# XMC4300 register map
Vendor: Infineon; File version: 1.1.0 (Reference Manual v1.1)
CPU: CM4 r2p0, little endian, MPU, FPU, 6 interrupt priority bits
Registers are 32-bit, read-write, reset 0x0 unless marked. A register's access mark holds for its fields unless they carry their own. Offsets are from the block's base; [hi:lo] are bit positions; 'fields as' and 'values as' point back to an identical list.

## SCU_CLK — System Control Unit
Base 0x50004600
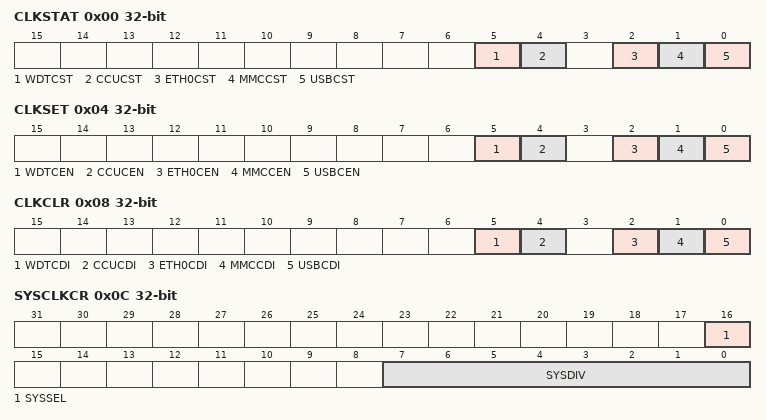
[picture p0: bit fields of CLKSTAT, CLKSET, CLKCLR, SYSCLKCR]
0x00 CLKSTAT ro — Clock Status Register
  [all] fields
    0=Const_0 (Clock disabled); 1=Const_1 (Clock enabled)
  [5] WDTCST — WDT Clock Status
  [4] CCUCST — CCU Clock Status
  [2] ETH0CST — Ethernet Clock Status
  [1] MMCCST — MMC Clock Status
  [0] USBCST — USB Clock Status
0x04 CLKSET wo
  [all] fields
    0=Const_0 (No effect); 1=Const_1 (Enable)
  [5] WDTCEN — WDT Clock Enable
  [4] CCUCEN — CCU Clock Enable
  [2] ETH0CEN — Ethernet Clock Enable
  [1] MMCCEN — MMC Clock Enable
  [0] USBCEN — USB Clock Enable
0x08 CLKCLR wo — CLK Clear Register
  [all] fields
    0=Const_0 (No effect); 1=Const_1 (Disable clock)
  [5] WDTCDI — WDT Clock Disable
  [4] CCUCDI — CCU Clock Disable
  [2] ETH0CDI — Ethernet Clock Disable
  [1] MMCCDI — MMC Clock Disable
  [0] USBCDI — USB Clock Disable
0x0C SYSCLKCR — System Clock Control Register
  [16] SYSSEL — System Clock Selection Value
    0=Const_0 (fOFI clock); 1=Const_1 (fPLL clock)
  [7:0] SYSDIV — System Clock Division Value
0x10 CPUCLKCR — CPU Clock Control Register
  [0] CPUDIV — CPU Clock Divider Enable
    0=Const_0 (fCPU = fSYS); 1=Const_1 (fCPU = fSYS / 2)
0x14 PBCLKCR — Peripheral Bus Clock Control Register
  [0] PBDIV — PB Clock Divider Enable
    0=Const_0 (fPERIPH = fCPU); 1=Const_1 (fPERIPH = fCPU / 2)
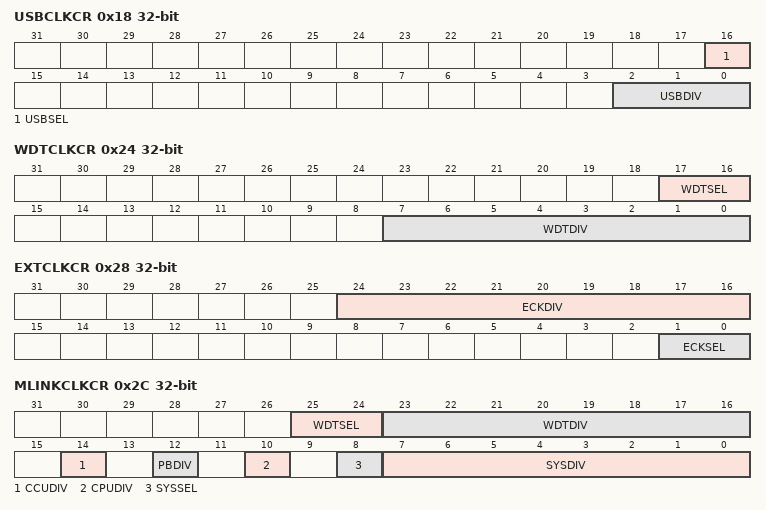
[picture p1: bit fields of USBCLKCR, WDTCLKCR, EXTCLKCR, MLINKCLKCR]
0x18 USBCLKCR — USB Clock Control Register
  [16] USBSEL — USB Clock Selection Value
    0=Const_0 (USB PLL Clock); 1=Const_1 (PLL Clock)
  [2:0] USBDIV — USB Clock Divider Value
0x20 CCUCLKCR — CCU Clock Control Register
  [0] CCUDIV — CCU Clock Divider Enable
    0=Const_0 (fCCU = fSYS); 1=Const_1 (fCCU = fSYS / 2)
0x24 WDTCLKCR — WDT Clock Control Register
  [17:16] WDTSEL — WDT Clock Selection Value
    0=Const_00 (fOFI clock); 1=Const_01 (fSTDBY clock); 2=Const_10 (fPLL clock)
  [7:0] WDTDIV — WDT Clock Divider Value
0x28 EXTCLKCR — External Clock Control
  [24:16] ECKDIV — External Clock Divider Value
  [1:0] ECKSEL — External Clock Selection Value
    0=Const_00 (fSYS clock); 2=Const_10 (fUSB clock divided according to ECKDIV bit field configuration); 3=Const_11 (fPLL clock divided according to ECKDIV bit field configuration)
0x2C MLINKCLKCR — Multi-Link Clock Control
  [25:24] WDTSEL — WDT Clock Selection Value
    values as WDTCLKCR.WDTSEL
  [23:16] WDTDIV — WDT Clock Divider Value
  [14] CCUDIV — CCU Clock Divider Enable
    0=Const_0 (fCCU = fSYS); 1=Const_1 (fCCU = fSYS / 2)
  [12] PBDIV — PB Clock Divider Enable
    0=Const_0 (fPERIPH = fCPU); 1=Const_1 (fPERIPH = fCPU / 2)
  [10] CPUDIV — CPU Clock Divider Enable
    0=Const_0 (fCPU = fSYS); 1=Const_1 (fCPU = fSYS / 2)
  [8] SYSSEL — System Clock Selection Value
    0=Const_0 (fOFI clock); 1=Const_1 (fPLL clock)
  [7:0] SYSDIV — System Clock Division Value
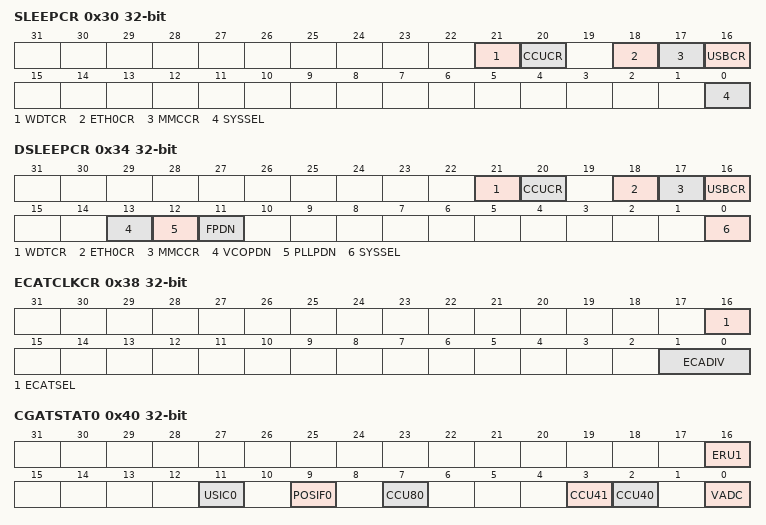
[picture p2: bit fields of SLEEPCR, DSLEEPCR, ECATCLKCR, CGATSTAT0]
0x30 SLEEPCR — Sleep Control Register
  [21] WDTCR — WDT Clock Control in Sleep Mode
    0=Const_0 (Disabled); 1=Const_1 (Enabled)
  [20] CCUCR — CCU Clock Control in Sleep Mode
    0=Const_0 (Disabled); 1=Const_1 (Enabled)
  [18] ETH0CR — Ethernet Clock Control in Sleep Mode
    0=Const_0 (Disabled); 1=Const_1 (Enabled)
  [17] MMCCR — MMC Clock Control in Sleep Mode
    0=Const_0 (Disabled); 1=Const_1 (Enabled)
  [16] USBCR — USB Clock Control in Sleep Mode
    0=Const_0 (Disabled); 1=Const_1 (Enabled)
  [0] SYSSEL — System Clock Selection Value
    0=Const_0 (fOFI clock); 1=Const_1 (fPLL clock)
0x34 DSLEEPCR — Deep Sleep Control Register
  [21] WDTCR — WDT Clock Control in Deep Sleep Mode
    0=Const_0 (Disabled); 1=Const_1 (Enabled)
  [20] CCUCR — CCU Clock Control in Deep Sleep Mode
    0=Const_0 (Disabled); 1=Const_1 (Enabled)
  [18] ETH0CR — Ethernet Clock Control in Deep Sleep Mode
    0=Const_0 (Disabled); 1=Const_1 (Enabled)
  [17] MMCCR — MMC Clock Control in Deep Sleep Mode
    0=Const_0 (Disabled); 1=Const_1 (Enabled)
  [16] USBCR — USB Clock Control in Deep Sleep Mode
    0=Const_0 (Disabled); 1=Const_1 (Enabled)
  [13] VCOPDN — VCO Power Down
    1=Const_1 (Switch off VCO of main PLL); 0=Const_0 (No effect)
  [12] PLLPDN — PLL Power Down
    1=Const_1 (Switch off main PLL); 0=Const_0 (No effect)
  [11] FPDN — Flash Power Down
    1=Const_1 (Flash power down module); 0=Const_0 (No effect)
  [0] SYSSEL — System Clock Selection Value
    0=Const_0 (fOFI clock); 1=Const_1 (fPLL clock)
0x38 ECATCLKCR — EtherCAT Clock Control Register
  [16] ECATSEL — EtherCAT Clock Selection Value
    0=Const_0 (fPLLUSB clock); 1=Const_1 (fPLL clock)
  [1:0] ECADIV — EtherCAT Clock Divider Value
0x40 CGATSTAT0 ro — Peripheral 0 Clock Gating Status
  [all] fields
    0=Const_0 (Gating de-asserted); 1=Const_1 (Gating asserted)
  [16] ERU1 — ERU1 Gating Status
  [11] USIC0 — USIC0 Gating Status
  [9] POSIF0 — POSIF0 Gating Status
  [7] CCU80 — CCU80 Gating Status
  [3] CCU41 — CCU41 Gating Status
  [2] CCU40 — CCU40 Gating Status
  [0] VADC — VADC Gating Status
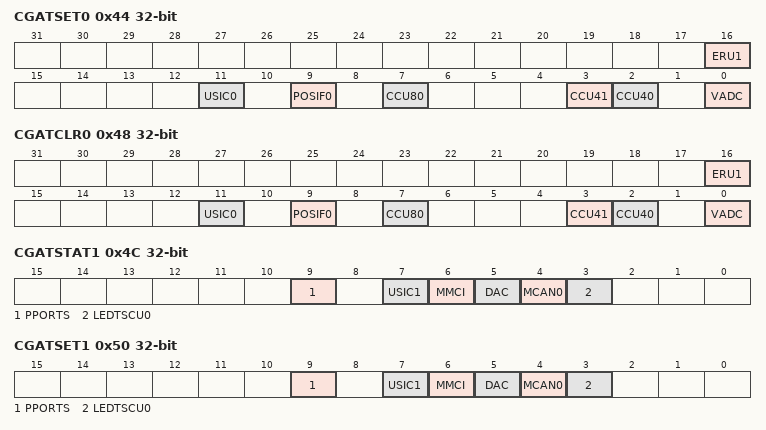
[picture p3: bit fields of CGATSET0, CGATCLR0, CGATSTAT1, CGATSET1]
0x44 CGATSET0 wo — Peripheral 0 Clock Gating Set
  [all] fields
    0=Const_0 (No effect); 1=Const_1 (Enable gating)
  [16] ERU1 — ERU1 Gating Set
  [11] USIC0 — USIC0 Gating Set
  [9] POSIF0 — POSIF0 Gating Set
  [7] CCU80 — CCU80 Gating Set
  [3] CCU41 — CCU41 Gating Set
  [2] CCU40 — CCU40 Gating Set
  [0] VADC — VADC Gating Set
0x48 CGATCLR0 wo — Peripheral 0 Clock Gating Clear
  [all] fields
    0=Const_0 (No effect); 1=Const_1 (Disable gating)
  [16] ERU1 — ERU1 Gating Clear
  [11] USIC0 — USIC0 Gating Clear
  [9] POSIF0 — POSIF0 Gating Clear
  [7] CCU80 — CCU80 Gating Clear
  [3] CCU41 — CCU41 Gating Clear
  [2] CCU40 — CCU40 Gating Clear
  [0] VADC — VADC Gating Clear
0x4C CGATSTAT1 ro — Peripheral 1 Clock Gating Status
  [all] fields
    0=Gating de-asserted; 1=Gating asserted
  [9] PPORTS — PORTS Gating Status
  [7] USIC1 — USIC1 Gating Status
  [6] MMCI — MMC Interface Gating Status
  [5] DAC — DAC Gating Status
  [4] MCAN0 — MultiCAN Gating Status
  [3] LEDTSCU0 — LEDTS Gating Status
0x50 CGATSET1 wo — Peripheral 1 Clock Gating Set
  [all] fields
    0=Const_0 (No effect); 1=Const_1 (Enable gating)
  [9] PPORTS — PORTS Gating Set
  [7] USIC1 — USIC1 Gating Set
  [6] MMCI — MMC Interface Gating Set
  [5] DAC — DAC Gating Set
  [4] MCAN0 — MultiCAN Gating Set
  [3] LEDTSCU0 — LEDTS Gating Set
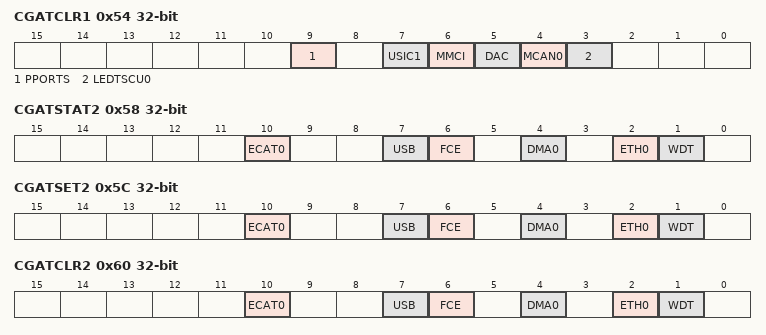
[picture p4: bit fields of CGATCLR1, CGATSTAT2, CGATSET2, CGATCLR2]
0x54 CGATCLR1 wo — Peripheral 1 Clock Gating Clear
  [all] fields
    0=Const_0 (No effect); 1=Const_1 (Disable gating)
  [9] PPORTS — PORTS Gating Clear
  [7] USIC1 — USIC1 Gating Clear
  [6] MMCI — MMC Interface Gating Clear
  [5] DAC — DAC Gating Clear
  [4] MCAN0 — MultiCAN Gating Clear
  [3] LEDTSCU0 — LEDTS Gating Clear
0x58 CGATSTAT2 ro — Peripheral 2 Clock Gating Status
  [all] fields
    0=Const_0 (Gating de-asserted); 1=Const_1 (Gating asserted)
  [10] ECAT0 — ECAT0 Gating Status
  [7] USB — USB Gating Status
  [6] FCE — FCE Gating Status
  [4] DMA0 — DMA0 Gating Status
  [2] ETH0 — ETH0 Gating Status
  [1] WDT — WDT Gating Status
0x5C CGATSET2 wo — Peripheral 2 Clock Gating Set
  [all] fields
    0=Const_0 (No effect); 1=Const_1 (Enable gating)
  [10] ECAT0 — ECAT0 Gating Set
  [7] USB — USB Gating Set
  [6] FCE — FCE Gating Set
  [4] DMA0 — DMA0 Gating Set
  [2] ETH0 — ETH0 Gating Set
  [1] WDT — WDT Gating Set
0x60 CGATCLR2 wo — Peripheral 2 Clock Gating Clear
  [all] fields
    0=Const_0 (No effect); 1=Const_1 (Disable gating)
  [10] ECAT0 — ECAT0 Gating Clear
  [7] USB — USB Gating Clear
  [6] FCE — FCE Gating Clear
  [4] DMA0 — DMA0 Gating Clear
  [2] ETH0 — ETH0 Gating Clear
  [1] WDT — WDT Gating Clear
